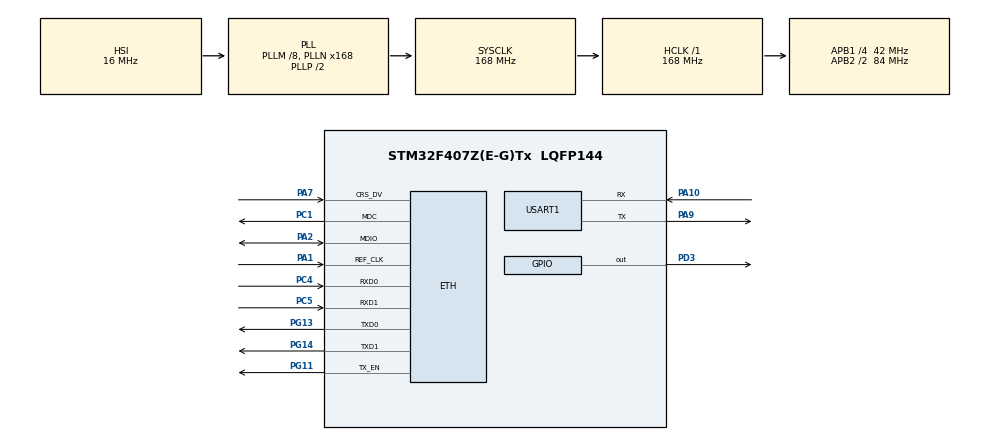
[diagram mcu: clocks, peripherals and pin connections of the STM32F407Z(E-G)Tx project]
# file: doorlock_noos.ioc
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ETH.MediaInterface=ETH_MEDIA_INTERFACE_RMII
ETH.PHY_Name_RMII=userPHY
ETH.PHY_User_Name=LAN8720
ETH.PhyAddress=0
LWIP.LWIP_DNS=1
LWIP.Version=v2.1.2_Cube
Mcu.Family=STM32F4
Mcu.Name=STM32F407Z(E-G)Tx
Mcu.Package=LQFP144
NVIC.PriorityGroup=NVIC_PRIORITYGROUP_4
NVIC.TIM6_DAC_IRQn=true\:0\:0\:false\:false\:true\:false\:true
NVIC.TimeBase=TIM6_DAC_IRQn
NVIC.TimeBaseIP=TIM6
PA1.Mode=RMII
PA1.Signal=ETH_REF_CLK
PA10.Mode=Asynchronous
PA10.Signal=USART1_RX
PA13.Mode=Serial_Wire
PA13.Signal=SYS_JTMS-SWDIO
PA14.Mode=Serial_Wire
PA14.Signal=SYS_JTCK-SWCLK
PA2.Mode=RMII
PA2.Signal=ETH_MDIO
PA7.Mode=RMII
PA7.Signal=ETH_CRS_DV
PA9.Mode=Asynchronous
PA9.Signal=USART1_TX
PC1.Mode=RMII
PC1.Signal=ETH_MDC
PC14-OSC32_IN.Mode=LSE-External-Clock-Source
PC14-OSC32_IN.Signal=RCC_OSC32_IN
PC15-OSC32_OUT.Mode=LSE-External-Clock-Source
PC15-OSC32_OUT.Signal=RCC_OSC32_OUT
PC4.Mode=RMII
PC4.Signal=ETH_RXD0
PC5.Mode=RMII
PC5.Signal=ETH_RXD1
PD3.Signal=GPIO_Output
PG11.Mode=RMII
PG11.Signal=ETH_TX_EN
PG13.Mode=RMII
PG13.Signal=ETH_TXD0
PG14.Mode=RMII
PG14.Signal=ETH_TXD1
PH0-OSC_IN.Mode=HSE-External-Clock-Source
PH0-OSC_IN.Signal=RCC_OSC_IN
PH1-OSC_OUT.Mode=HSE-External-Clock-Source
PH1-OSC_OUT.Signal=RCC_OSC_OUT
ProjectManager.HeapSize=0x4000
ProjectManager.StackSize=0x400
ProjectManager.TargetToolchain=MDK-ARM V5
RCC.48MHZClocksFreq_Value=84000000
RCC.AHBFreq_Value=168000000
RCC.APB1CLKDivider=RCC_HCLK_DIV4
RCC.APB1Freq_Value=42000000
RCC.APB1TimFreq_Value=84000000
RCC.APB2CLKDivider=RCC_HCLK_DIV2
RCC.APB2Freq_Value=84000000
RCC.APB2TimFreq_Value=168000000
RCC.CortexFreq_Value=168000000
RCC.HCLKFreq_Value=168000000
RCC.HSE_VALUE=8000000
RCC.HSI_VALUE=16000000
RCC.LSE_VALUE=32768
RCC.PLLM=8
RCC.PLLN=168
RCC.SYSCLKFreq_VALUE=168000000
RCC.SYSCLKSource=RCC_SYSCLKSOURCE_PLLCLK
RCC.VCOOutputFreq_Value=336000000
USART1.VirtualMode=VM_ASYNC
VP_LWIP_VS_Enabled.Mode=Enabled
VP_SYS_VS_tim6.Mode=TIM6
board=custom

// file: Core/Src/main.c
/* USER CODE BEGIN Header */
/**
  ******************************************************************************
  * @file           : main.c
  * @brief          : Main program body
  ******************************************************************************
  * @attention
  *
  * <h2><center>&copy; Copyright (c) 2020 STMicroelectronics.
  * All rights reserved.</center></h2>
  *
  * This software component is licensed by ST under Ultimate Liberty license
  * SLA0044, the "License"; You may not use this file except in compliance with
  * the License. You may obtain a copy of the License at:
  *                             www.st.com/SLA0044
  *
  ******************************************************************************
  */
/* USER CODE END Header */
#include "main.h"
#include "lwip.h"

/* USER CODE BEGIN PTD */
uint8_t gMacAddress[6] = { 0x00, 0x80, 0xe1, 0x00, 0x00, 0x01};
/* USER CODE END PTD */

UART_HandleTypeDef huart1;

void SystemClock_Config(void);
static void MX_GPIO_Init(void);
static void MX_USART1_UART_Init(void);

int main(void)
{

  /* MCU Configuration--------------------------------------------------------*/

  /* Reset of all peripherals, Initializes the Flash interface and the Systick. */
  HAL_Init();

  /* Configure the system clock */
  SystemClock_Config();

  /* Initialize all configured peripherals */
  MX_GPIO_Init();
  MX_USART1_UART_Init();
  MX_LWIP_Init();

  /* Infinite loop */
  /* USER CODE BEGIN WHILE */
  printf("running!!!!!!!!!!!!!!!\r\n");

  while (1)
  {
    /* USER CODE END WHILE */

    /* USER CODE BEGIN 3 */
    MX_LWIP_Process();
    //HAL_Delay(1);
  }
  /* USER CODE END 3 */
}

void SystemClock_Config(void)
{
  RCC_OscInitTypeDef RCC_OscInitStruct = {0};
  RCC_ClkInitTypeDef RCC_ClkInitStruct = {0};

  /** Configure the main internal regulator output voltage
  */
  __HAL_RCC_PWR_CLK_ENABLE();
  __HAL_PWR_VOLTAGESCALING_CONFIG(PWR_REGULATOR_VOLTAGE_SCALE1);
  /** Initializes the RCC Oscillators according to the specified parameters
  * in the RCC_OscInitTypeDef structure.
  */
  RCC_OscInitStruct.OscillatorType = RCC_OSCILLATORTYPE_HSI;
  RCC_OscInitStruct.HSIState = RCC_HSI_ON;
  RCC_OscInitStruct.HSICalibrationValue = RCC_HSICALIBRATION_DEFAULT;
  RCC_OscInitStruct.PLL.PLLState = RCC_PLL_ON;
  RCC_OscInitStruct.PLL.PLLSource = RCC_PLLSOURCE_HSI;
  RCC_OscInitStruct.PLL.PLLM = 8;
  RCC_OscInitStruct.PLL.PLLN = 168;
  RCC_OscInitStruct.PLL.PLLP = RCC_PLLP_DIV2;
  RCC_OscInitStruct.PLL.PLLQ = 4;
  if (HAL_RCC_OscConfig(&RCC_OscInitStruct) != HAL_OK)
  {
    Error_Handler();
  }
  /** Initializes the CPU, AHB and APB buses clocks
  */
  RCC_ClkInitStruct.ClockType = RCC_CLOCKTYPE_HCLK|RCC_CLOCKTYPE_SYSCLK
                              |RCC_CLOCKTYPE_PCLK1|RCC_CLOCKTYPE_PCLK2;
  RCC_ClkInitStruct.SYSCLKSource = RCC_SYSCLKSOURCE_PLLCLK;
  RCC_ClkInitStruct.AHBCLKDivider = RCC_SYSCLK_DIV1;
  RCC_ClkInitStruct.APB1CLKDivider = RCC_HCLK_DIV4;
  RCC_ClkInitStruct.APB2CLKDivider = RCC_HCLK_DIV2;

  if (HAL_RCC_ClockConfig(&RCC_ClkInitStruct, FLASH_LATENCY_5) != HAL_OK)
  {
    Error_Handler();
  }
}

static void MX_USART1_UART_Init(void)
{

  huart1.Instance = USART1;
  huart1.Init.BaudRate = 115200;
  huart1.Init.WordLength = UART_WORDLENGTH_8B;
  huart1.Init.StopBits = UART_STOPBITS_1;
  huart1.Init.Parity = UART_PARITY_NONE;
  huart1.Init.Mode = UART_MODE_TX_RX;
  huart1.Init.HwFlowCtl = UART_HWCONTROL_NONE;
  huart1.Init.OverSampling = UART_OVERSAMPLING_16;
  if (HAL_UART_Init(&huart1) != HAL_OK)
  {
    Error_Handler();
  }

}

static void MX_GPIO_Init(void)
{
  GPIO_InitTypeDef GPIO_InitStruct = {0};

  /* GPIO Ports Clock Enable */
  __HAL_RCC_GPIOC_CLK_ENABLE();
  __HAL_RCC_GPIOH_CLK_ENABLE();
  __HAL_RCC_GPIOA_CLK_ENABLE();
  __HAL_RCC_GPIOD_CLK_ENABLE();
  __HAL_RCC_GPIOG_CLK_ENABLE();

  /*Configure GPIO pin Output Level */
  HAL_GPIO_WritePin(GPIOD, GPIO_PIN_3, GPIO_PIN_RESET);

  /*Configure GPIO pin : PD3 */
  GPIO_InitStruct.Pin = GPIO_PIN_3;
  GPIO_InitStruct.Mode = GPIO_MODE_OUTPUT_PP;
  GPIO_InitStruct.Pull = GPIO_NOPULL;
  GPIO_InitStruct.Speed = GPIO_SPEED_FREQ_LOW;
  HAL_GPIO_Init(GPIOD, &GPIO_InitStruct);

}

/* USER CODE BEGIN 4 */

int fputc(int ch, FILE *f)
{
  HAL_UART_Transmit(&huart1, (uint8_t *)&ch, 1, 0xffff);
  //LL_USART_TransmitData8(USART1, (uint8_t)ch);
  //while(!LL_USART_IsActiveFlag_TC(USART1));
  return (ch);
}

/* USER CODE END 4 */

void HAL_TIM_PeriodElapsedCallback(TIM_HandleTypeDef *htim)
{
  if (htim->Instance == TIM6) {
    HAL_IncTick();
  }
}

void Error_Handler(void)
{
}

/************************ (C) COPYRIGHT STMicroelectronics *****END OF FILE****/
